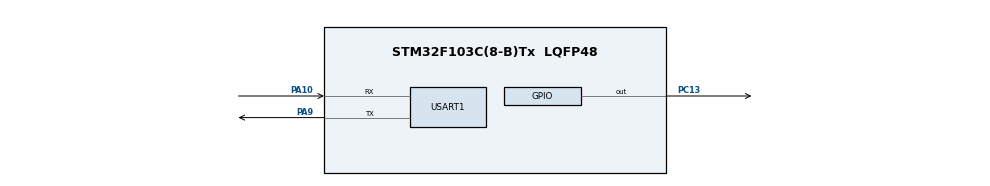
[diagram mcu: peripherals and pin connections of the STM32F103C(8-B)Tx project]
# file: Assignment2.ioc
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Mcu.Family=STM32F1
Mcu.Name=STM32F103C(8-B)Tx
Mcu.Package=LQFP48
NVIC.PriorityGroup=NVIC_PRIORITYGROUP_4
PA10.Mode=Asynchronous
PA10.Signal=USART1_RX
PA9.Mode=Asynchronous
PA9.Signal=USART1_TX
PC13-TAMPER-RTC.Signal=GPIO_Output
ProjectManager.HeapSize=0x200
ProjectManager.StackSize=0x400
ProjectManager.TargetToolchain=CMake
RCC.APB1Freq_Value=8000000
RCC.APB2Freq_Value=8000000
USART1.VirtualMode=VM_ASYNC
VP_SYS_VS_ND.Mode=No_Debug
board=custom

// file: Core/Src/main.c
/* USER CODE BEGIN Header */
/**
  ******************************************************************************
  * @file           : main.c
  * @brief          : Main program body
  ******************************************************************************
  * @attention
  *
  * Copyright (c) 2026 STMicroelectronics.
  * All rights reserved.
  *
  * This software is licensed under terms that can be found in the LICENSE file
  * in the root directory of this software component.
  * If no LICENSE file comes with this software, it is provided AS-IS.
  *
  ******************************************************************************
  */
/* USER CODE END Header */
#include "main.h"

/* USER CODE BEGIN Includes */
#include "os.h"
#include "stdio.h"
#include "string.h"
/* USER CODE END Includes */

UART_HandleTypeDef huart1;

/* USER CODE BEGIN PV */
  Queue queue;
  BinarySemaphore sem;
/* USER CODE END PV */

void SystemClock_Config(void);
static void MX_GPIO_Init(void);
static void MX_USART1_UART_Init(void);
/* USER CODE BEGIN PFP */
  void heartbeat_task(void);
  void task_1(void);
  void task_2(void);
  void uart_task(void);
/* USER CODE END PFP */

/* USER CODE BEGIN 0 */
  void heartbeat_task(void){
      // printf("Heartbeat\n");
      char my_msg[] = "Heartbeat\r\n";
      HAL_UART_Transmit(&huart1, (uint8_t*)my_msg, sizeof(my_msg) - 1, HAL_MAX_DELAY);
      HAL_GPIO_TogglePin(GPIOC, GPIO_PIN_13);
      os_sleep(1000);
  }

  void task_1(void){
      static int count = 0;

      // printf("Enqueued value: %d\n", count);
      enqueue(&queue, count);

      char msg[16];
      sprintf(msg, "Enqueued: %d\r\n", count);
      HAL_UART_Transmit(&huart1, (uint8_t*)msg, strlen(msg), HAL_MAX_DELAY);

      count++;
      sem_post(&sem);
      os_sleep(5000);
      if(os_yield()) return;
  }

  void task_2(void){
      int value;

      if(!sem_wait(&sem)){
          return;
      }

      if(dequeue(&queue, &value) == 0){
          // printf("Dequeued value: %d\n", value);
          char msg[16];
          sprintf(msg, "dEnqueued: %d\r\n", value);
          HAL_UART_Transmit(&huart1, (uint8_t*)msg, strlen(msg), HAL_MAX_DELAY);
      }
      os_sleep(5000);
      if(os_yield()) return;

  }

void uart_task(void){
    static char rx_buffer[20];
    static int i = 0;
    char c;

    if (HAL_UART_Receive(&huart1, (uint8_t*)&c, 1, 0) == HAL_OK) {
        HAL_UART_Transmit(&huart1, (uint8_t*)&c, 1, 100);

        if (c != '\r' && c != '\n') {
            rx_buffer[i++] = c;
            if (i >= (int)sizeof(rx_buffer)-1)
                i = (int)sizeof(rx_buffer)-2;
        } else {
            rx_buffer[i] = '\0';
            i = 0;

            if(strcmp(rx_buffer, "status") == 0){
                char msg[64];
                sprintf(msg,"SysTicks: %lu\r\nQueue: %d\r\nSemaphore: %d\r\n",
                    os_now(), queue.count, sem.value);
                HAL_UART_Transmit(&huart1,(uint8_t*)msg,strlen(msg),HAL_MAX_DELAY);
            }
            else if(strcmp(rx_buffer, "tasks") == 0){
                TCB *tasks = os_get_task_list();
                int count = os_get_task_count();
                for(int j = 0; j < count; j++){
                    char msg[64];
                    sprintf(msg,"Task %d : %s\r\n", j, tasks[j].name);
                    HAL_UART_Transmit(&huart1,(uint8_t*)msg,strlen(msg),HAL_MAX_DELAY);
                }
            }
            else if(strcmp(rx_buffer, "state") == 0){
                TCB *tasks = os_get_task_list();
                int count = os_get_task_count();
                for(int j = 0; j < count; j++){
                    char *state;
                    switch(tasks[j].state){
                        case READY:    state = "READY";   break;
                        case RUNNING:  state = "RUNNING"; break;
                        case SLEEPING: state = "SLEEPING";break;
                        case BLOCKED:  state = "BLOCKED"; break;
                        default:       state = "UNKNOWN"; break;
                    }
                    char msg[80];
                    sprintf(msg,"%s : %s | Wakeup: %lu\r\n",
                        tasks[j].name, state,
                        (unsigned long)tasks[j].wakeup_time);
                    HAL_UART_Transmit(&huart1,(uint8_t*)msg,strlen(msg),HAL_MAX_DELAY);
                }
            }
            else if(strcmp(rx_buffer, "help") == 0){
                char msg[] = "Commands:\r\nhelp   - Show commands\r\n"
                             "status - OS status\r\n"
                             "tasks  - List tasks\r\n"
                             "state  - Task states\r\n"
                             "tick   - Current system tick\r\n"
                             "queue  - Queue information\r\n"
                             "about  - Project information\r\n";
                HAL_UART_Transmit(&huart1,(uint8_t*)msg,sizeof(msg)-1,HAL_MAX_DELAY);
            }
            else if(strcmp(rx_buffer, "about") == 0){
                char msg[] = "Simple Cooperative RTOS\r\n"
                             "Priority Scheduler\r\n"
                             "Binary Semaphore + Queue\r\n";
                HAL_UART_Transmit(&huart1,(uint8_t*)msg,strlen(msg),HAL_MAX_DELAY);
            }
            else if(strcmp(rx_buffer, "tick") == 0){
                char msg[32];
                sprintf(msg,"Tick: %lu\r\n",(unsigned long)os_now());
                HAL_UART_Transmit(&huart1,(uint8_t*)msg,strlen(msg),HAL_MAX_DELAY);
            }
            else if(strcmp(rx_buffer, "queue") == 0){
                char msg[64];
                sprintf(msg,"Count:%d Head:%d Tail:%d\r\n",
                    queue.count, queue.head, queue.tail);
                HAL_UART_Transmit(&huart1,(uint8_t*)msg,strlen(msg),HAL_MAX_DELAY);
            }
        }

    } else {
        os_sleep(50);
    }

    if (os_yield()) return;
}

/* USER CODE END 0 */

int main(void)
{

  /* MCU Configuration--------------------------------------------------------*/

  /* Reset of all peripherals, Initializes the Flash interface and the Systick. */
  HAL_Init();

  /* Configure the system clock */
  SystemClock_Config();

  /* USER CODE BEGIN SysInit */
  __HAL_AFIO_REMAP_SWJ_ENABLE();
  /* USER CODE END SysInit */

  /* Initialize all configured peripherals */
  MX_GPIO_Init();
  MX_USART1_UART_Init();

  /* Infinite loop */
  /* USER CODE BEGIN WHILE */
  // while (1)
  // {
  //   /* USER CODE END WHILE */

  //   /* USER CODE BEGIN 3 */
  // }
    os_init();

    queue_init(&queue);
    sem_init(&sem);

    os_task_create(heartbeat_task, 1, "Heartbeat");
    os_task_create(task_1, 2, "Task 1");
    os_task_create(task_2, 2, "Task 2");
    os_task_create(uart_task, 3, "UART_Task");

    os_start();
  /* USER CODE END 3 */
}

void SystemClock_Config(void)
{
  RCC_OscInitTypeDef RCC_OscInitStruct = {0};
  RCC_ClkInitTypeDef RCC_ClkInitStruct = {0};

  /** Initializes the RCC Oscillators according to the specified parameters
  * in the RCC_OscInitTypeDef structure.
  */
  RCC_OscInitStruct.OscillatorType = RCC_OSCILLATORTYPE_HSI;
  RCC_OscInitStruct.HSIState = RCC_HSI_ON;
  RCC_OscInitStruct.HSICalibrationValue = RCC_HSICALIBRATION_DEFAULT;
  RCC_OscInitStruct.PLL.PLLState = RCC_PLL_NONE;
  if (HAL_RCC_OscConfig(&RCC_OscInitStruct) != HAL_OK)
  {
    Error_Handler();
  }

  /** Initializes the CPU, AHB and APB buses clocks
  */
  RCC_ClkInitStruct.ClockType = RCC_CLOCKTYPE_HCLK|RCC_CLOCKTYPE_SYSCLK
                              |RCC_CLOCKTYPE_PCLK1|RCC_CLOCKTYPE_PCLK2;
  RCC_ClkInitStruct.SYSCLKSource = RCC_SYSCLKSOURCE_HSI;
  RCC_ClkInitStruct.AHBCLKDivider = RCC_SYSCLK_DIV1;
  RCC_ClkInitStruct.APB1CLKDivider = RCC_HCLK_DIV1;
  RCC_ClkInitStruct.APB2CLKDivider = RCC_HCLK_DIV1;

  if (HAL_RCC_ClockConfig(&RCC_ClkInitStruct, FLASH_LATENCY_0) != HAL_OK)
  {
    Error_Handler();
  }
}

static void MX_USART1_UART_Init(void)
{

  huart1.Instance = USART1;
  huart1.Init.BaudRate = 115200;
  huart1.Init.WordLength = UART_WORDLENGTH_8B;
  huart1.Init.StopBits = UART_STOPBITS_1;
  huart1.Init.Parity = UART_PARITY_NONE;
  huart1.Init.Mode = UART_MODE_TX_RX;
  huart1.Init.HwFlowCtl = UART_HWCONTROL_NONE;
  huart1.Init.OverSampling = UART_OVERSAMPLING_16;
  if (HAL_UART_Init(&huart1) != HAL_OK)
  {
    Error_Handler();
  }

}

static void MX_GPIO_Init(void)
{
  GPIO_InitTypeDef GPIO_InitStruct = {0};

  /* GPIO Ports Clock Enable */
  __HAL_RCC_GPIOC_CLK_ENABLE();
  __HAL_RCC_GPIOA_CLK_ENABLE();

  /*Configure GPIO pin Output Level */
  HAL_GPIO_WritePin(GPIOC, GPIO_PIN_13, GPIO_PIN_RESET);

  /*Configure GPIO pin : PC13 */
  GPIO_InitStruct.Pin = GPIO_PIN_13;
  GPIO_InitStruct.Mode = GPIO_MODE_OUTPUT_PP;
  GPIO_InitStruct.Pull = GPIO_NOPULL;
  GPIO_InitStruct.Speed = GPIO_SPEED_FREQ_LOW;
  HAL_GPIO_Init(GPIOC, &GPIO_InitStruct);

}

void Error_Handler(void)
{
  __disable_irq();
  while (1)
  {
  }
}
